VERSION "HIPBNYYYYYYYYYYYYYYYYYYYYYYYYYYYYYYYYYYYYY/4/%%%/4/'%**4YYY///"

NS_ :

BS_:

BU_:

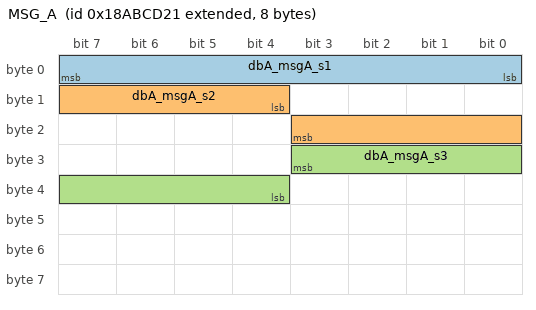
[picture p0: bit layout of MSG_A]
BO_ 2561396001 MSG_A: 8 Vector__XXX
 SG_ dbA_msgA_s1 : 0|8@1+ (1,0) [0|0] "" Vector__XXX
 SG_ dbA_msgA_s2 : 12|8@1+ (1,0) [0|0] "" Vector__XXX
 SG_ dbA_msgA_s3 : 27|8@0- (1,0) [0|0] "" Vector__XXX

BO_ 2566839392 MSG_B: 8 Vector__XXX
 SG_ dbA_msgB_s1 : 2|16@1+ (1,0) [0|0] "" Vector__XXX

BO_ 2147484432 MSG_C: 8 Vector__XXX
 SG_ NewSignal4_A : 0|8@1+ (1,0) [0|0] "" Vector__XXX

CM_ BO_ 2561396001 "Same PGN";
CM_ SG_ 2561396001 dbA_msgA_s2 "same";
CM_ SG_ 2561396001 dbA_msgA_s3 "Motorola";
CM_ BO_ 2566839392 "Same Frame";
CM_ BO_ 2147484432 "Nothing";
